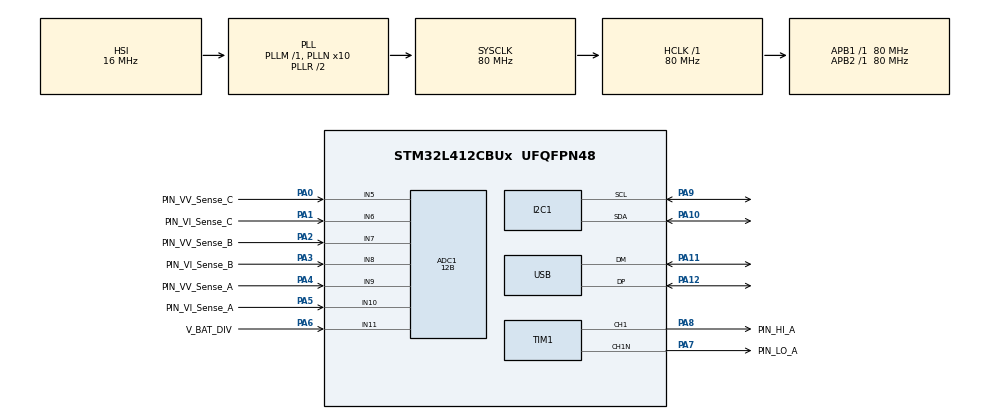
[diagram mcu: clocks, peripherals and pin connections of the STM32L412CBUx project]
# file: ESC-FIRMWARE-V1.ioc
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ADC1.Channel-0\#ChannelRegularConversion=ADC_CHANNEL_11
ADC1.ClockPrescaler=ADC_CLOCK_ASYNC_DIV1
ADC1.ContinuousConvMode=ENABLE
ADC1.DMAContinuousRequests=ENABLE
ADC1.NbrOfConversionFlag=1
ADC1.OffsetNumber-0\#ChannelRegularConversion=ADC_OFFSET_NONE
ADC1.Overrun=ADC_OVR_DATA_OVERWRITTEN
ADC1.Rank-0\#ChannelRegularConversion=1
ADC1.Resolution=ADC_RESOLUTION_12B
ADC1.SamplingTime-0\#ChannelRegularConversion=ADC_SAMPLETIME_2CYCLES_5
ADC1.master=1
Dma.ADC1.0.Direction=DMA_PERIPH_TO_MEMORY
Dma.ADC1.0.Instance=DMA1_Channel1
Dma.ADC1.0.MemDataAlignment=DMA_MDATAALIGN_HALFWORD
Dma.ADC1.0.MemInc=DMA_MINC_ENABLE
Dma.ADC1.0.Mode=DMA_CIRCULAR
Dma.ADC1.0.PeriphDataAlignment=DMA_PDATAALIGN_HALFWORD
Dma.ADC1.0.PeriphInc=DMA_PINC_DISABLE
Dma.ADC1.0.Priority=DMA_PRIORITY_LOW
Dma.Request0=ADC1
I2C1.Timing=0x10D19CE4
Mcu.Family=STM32L4
Mcu.Name=STM32L412CBUx
Mcu.Package=UFQFPN48
NVIC.DMA1_Channel1_IRQn=true\:0\:0\:false\:false\:true\:false\:true\:true
NVIC.PriorityGroup=NVIC_PRIORITYGROUP_4
NVIC.USB_IRQn=true\:0\:0\:false\:false\:true\:false\:true\:true
PA0.GPIO_Label=PIN_VV_Sense_C
PA0.Signal=ADCx_IN5
PA1.GPIO_Label=PIN_VI_Sense_C
PA1.Signal=ADCx_IN6
PA10.Mode=I2C
PA10.Signal=I2C1_SDA
PA11.Mode=Device
PA11.Signal=USB_DM
PA12.Mode=Device
PA12.Signal=USB_DP
PA13\ (JTMS/SWDIO).Mode=Serial_Wire
PA13\ (JTMS/SWDIO).Signal=SYS_JTMS-SWDIO
PA14\ (JTCK/SWCLK).Mode=Serial_Wire
PA14\ (JTCK/SWCLK).Signal=SYS_JTCK-SWCLK
PA2.GPIO_Label=PIN_VV_Sense_B
PA2.Signal=ADCx_IN7
PA3.GPIO_Label=PIN_VI_Sense_B
PA3.Signal=ADCx_IN8
PA4.GPIO_Label=PIN_VV_Sense_A
PA4.Signal=ADCx_IN9
PA5.GPIO_Label=PIN_VI_Sense_A
PA5.Signal=ADCx_IN10
PA6.GPIO_Label=V_BAT_DIV
PA6.Signal=ADCx_IN11
PA7.GPIO_Label=PIN_LO_A
PA7.Mode=PWM Generation1 CH1 CH1N
PA7.Signal=TIM1_CH1N
PA8.GPIO_Label=PIN_HI_A
PA8.Signal=S_TIM1_CH1
PA9.Mode=I2C
PA9.Signal=I2C1_SCL
PH0-OSC_IN\ (PH0).Mode=HSE-External-Oscillator
PH0-OSC_IN\ (PH0).Signal=RCC_OSC_IN
PH1-OSC_OUT\ (PH1).Mode=HSE-External-Oscillator
PH1-OSC_OUT\ (PH1).Signal=RCC_OSC_OUT
ProjectManager.HeapSize=0x200
ProjectManager.StackSize=0x400
ProjectManager.TargetToolchain=CMake
RCC.ADCFreq_Value=80000000
RCC.AHBFreq_Value=80000000
RCC.APB1Freq_Value=80000000
RCC.APB1TimFreq_Value=80000000
RCC.APB2Freq_Value=80000000
RCC.APB2TimFreq_Value=80000000
RCC.CortexFreq_Value=80000000
RCC.HCLKFreq_Value=80000000
RCC.HSE_VALUE=12000000
RCC.HSI48_VALUE=48000000
RCC.HSI_VALUE=16000000
RCC.LSE_VALUE=32768
RCC.MSIClockRange=RCC_MSIRANGE_11
RCC.MSI_VALUE=48000000
RCC.PLLN=10
RCC.PLLSourceVirtual=RCC_PLLSOURCE_HSI
RCC.SYSCLKFreq_VALUE=80000000
RCC.SYSCLKSource=RCC_SYSCLKSOURCE_PLLCLK
RCC.USBFreq_Value=48000000
RCC.VCOOutputFreq_Value=160000000
SH.ADCx_IN10.0=ADC1_IN10,IN10-Single-Ended
SH.ADCx_IN11.0=ADC1_IN11,IN11-Single-Ended
SH.ADCx_IN11.1=ADC2_IN11
SH.ADCx_IN5.0=ADC1_IN5,IN5-Single-Ended
SH.ADCx_IN6.0=ADC1_IN6,IN6-Single-Ended
SH.ADCx_IN7.0=ADC1_IN7,IN7-Single-Ended
SH.ADCx_IN8.0=ADC1_IN8,IN8-Single-Ended
SH.ADCx_IN9.0=ADC1_IN9,IN9-Single-Ended
SH.S_TIM1_CH1.0=TIM1_CH1,PWM Generation1 CH1 CH1N
TIM1.Channel-PWM\ Generation1\ CH1\ CH1N=TIM_CHANNEL_1
USB_DEVICE.CLASS_NAME_FS=CDC
USB_DEVICE.CONFIGURATION_STRING_CDC_FS=ESC FIRMWARE V1
USB_DEVICE.PRODUCT_STRING_CDC_FS=ESC COM PORT
USB_DEVICE.USBD_DEBUG_LEVEL=3
USB_DEVICE.VirtualMode=Cdc
USB_DEVICE.VirtualModeFS=Cdc_FS
VP_ADC1_Vbat_Input.Mode=IN-Vbat
VP_TIM1_VS_ClockSourceINT.Mode=Internal
VP_USB_DEVICE_VS_USB_DEVICE_CDC_FS.Mode=CDC_FS
board=custom

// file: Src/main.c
/* USER CODE BEGIN Header */
/**
 ******************************************************************************
 * @file           : main.c
 * @brief          : Main program body
 ******************************************************************************
 * @attention
 *
 * Copyright (c) 2024 STMicroelectronics.
 * All rights reserved.
 *
 * This software is licensed under terms that can be found in the LICENSE file
 * in the root directory of this software component.
 * If no LICENSE file comes with this software, it is provided AS-IS.
 *
 ******************************************************************************
 */
/* USER CODE END Header */
#include "main.h"
#include "usb_device.h"

/* USER CODE BEGIN PD */
#define ADC_BUF_LEN 4096
/* USER CODE END PD */

ADC_HandleTypeDef hadc1;
DMA_HandleTypeDef hdma_adc1;

I2C_HandleTypeDef hi2c1;

TIM_HandleTypeDef htim1;

/* USER CODE BEGIN PV */
uint16_t adc_buf[ADC_BUF_LEN];
/* USER CODE END PV */

void SystemClock_Config(void);
static void MX_GPIO_Init(void);
static void MX_DMA_Init(void);
static void MX_ADC1_Init(void);
static void MX_I2C1_Init(void);
static void MX_TIM1_Init(void);

int main(void)
{

  /* MCU Configuration--------------------------------------------------------*/

  /* Reset of all peripherals, Initializes the Flash interface and the Systick. */
  HAL_Init();

  /* Configure the system clock */
  SystemClock_Config();

  /* Initialize all configured peripherals */
  MX_GPIO_Init();
  MX_DMA_Init();
  MX_USB_DEVICE_Init();
  MX_ADC1_Init();
  MX_I2C1_Init();
  MX_TIM1_Init();
  /* USER CODE BEGIN 2 */
  HAL_Delay(200);
  printf("ESC_FIRMWARE_V1\n");
  /* USER CODE END 2 */

  /* Infinite loop */
  while (1)
  {

  }
}

// Called when first half of buffer is filled
void HAL_ADC_ConvHalfCpltCallback(ADC_HandleTypeDef *hadc)
{
  printf("first half of buffer is filled\n");
}

// Called when buffer is completely filled
void HAL_ADC_ConvCpltCallback(ADC_HandleTypeDef *hadc)
{
  printf("buffer is completely filled\n");
}

void SystemClock_Config(void)
{
  RCC_OscInitTypeDef RCC_OscInitStruct = {0};
  RCC_ClkInitTypeDef RCC_ClkInitStruct = {0};

  /** Configure the main internal regulator output voltage
   */
  if (HAL_PWREx_ControlVoltageScaling(PWR_REGULATOR_VOLTAGE_SCALE1) != HAL_OK)
  {
    Error_Handler();
  }

  /** Initializes the RCC Oscillators according to the specified parameters
   * in the RCC_OscInitTypeDef structure.
   */
  RCC_OscInitStruct.OscillatorType = RCC_OSCILLATORTYPE_HSI | RCC_OSCILLATORTYPE_MSI;
  RCC_OscInitStruct.HSIState = RCC_HSI_ON;
  RCC_OscInitStruct.HSICalibrationValue = RCC_HSICALIBRATION_DEFAULT;
  RCC_OscInitStruct.MSIState = RCC_MSI_ON;
  RCC_OscInitStruct.MSICalibrationValue = 0;
  RCC_OscInitStruct.MSIClockRange = RCC_MSIRANGE_11;
  RCC_OscInitStruct.PLL.PLLState = RCC_PLL_ON;
  RCC_OscInitStruct.PLL.PLLSource = RCC_PLLSOURCE_HSI;
  RCC_OscInitStruct.PLL.PLLM = 1;
  RCC_OscInitStruct.PLL.PLLN = 10;
  RCC_OscInitStruct.PLL.PLLQ = RCC_PLLQ_DIV2;
  RCC_OscInitStruct.PLL.PLLR = RCC_PLLR_DIV2;
  if (HAL_RCC_OscConfig(&RCC_OscInitStruct) != HAL_OK)
  {
    Error_Handler();
  }

  /** Initializes the CPU, AHB and APB buses clocks
   */
  RCC_ClkInitStruct.ClockType = RCC_CLOCKTYPE_HCLK | RCC_CLOCKTYPE_SYSCLK | RCC_CLOCKTYPE_PCLK1 | RCC_CLOCKTYPE_PCLK2;
  RCC_ClkInitStruct.SYSCLKSource = RCC_SYSCLKSOURCE_PLLCLK;
  RCC_ClkInitStruct.AHBCLKDivider = RCC_SYSCLK_DIV1;
  RCC_ClkInitStruct.APB1CLKDivider = RCC_HCLK_DIV1;
  RCC_ClkInitStruct.APB2CLKDivider = RCC_HCLK_DIV1;

  if (HAL_RCC_ClockConfig(&RCC_ClkInitStruct, FLASH_LATENCY_4) != HAL_OK)
  {
    Error_Handler();
  }
}

static void MX_ADC1_Init(void)
{

  ADC_MultiModeTypeDef multimode = {0};
  ADC_ChannelConfTypeDef sConfig = {0};

  /** Common config
   */
  hadc1.Instance = ADC1;
  hadc1.Init.ClockPrescaler = ADC_CLOCK_ASYNC_DIV1;
  hadc1.Init.Resolution = ADC_RESOLUTION_12B;
  hadc1.Init.DataAlign = ADC_DATAALIGN_RIGHT;
  hadc1.Init.ScanConvMode = ADC_SCAN_DISABLE;
  hadc1.Init.EOCSelection = ADC_EOC_SINGLE_CONV;
  hadc1.Init.LowPowerAutoWait = DISABLE;
  hadc1.Init.ContinuousConvMode = ENABLE;
  hadc1.Init.NbrOfConversion = 1;
  hadc1.Init.DiscontinuousConvMode = DISABLE;
  hadc1.Init.ExternalTrigConv = ADC_SOFTWARE_START;
  hadc1.Init.ExternalTrigConvEdge = ADC_EXTERNALTRIGCONVEDGE_NONE;
  hadc1.Init.DMAContinuousRequests = ENABLE;
  hadc1.Init.Overrun = ADC_OVR_DATA_OVERWRITTEN;
  hadc1.Init.OversamplingMode = DISABLE;
  if (HAL_ADC_Init(&hadc1) != HAL_OK)
  {
    Error_Handler();
  }

  /** Configure the ADC multi-mode
   */
  multimode.Mode = ADC_MODE_INDEPENDENT;
  if (HAL_ADCEx_MultiModeConfigChannel(&hadc1, &multimode) != HAL_OK)
  {
    Error_Handler();
  }

  /** Configure Regular Channel
   */
  sConfig.Channel = ADC_CHANNEL_11;
  sConfig.Rank = ADC_REGULAR_RANK_1;
  sConfig.SamplingTime = ADC_SAMPLETIME_2CYCLES_5;
  sConfig.SingleDiff = ADC_SINGLE_ENDED;
  sConfig.OffsetNumber = ADC_OFFSET_NONE;
  sConfig.Offset = 0;
  if (HAL_ADC_ConfigChannel(&hadc1, &sConfig) != HAL_OK)
  {
    Error_Handler();
  }
}

static void MX_I2C1_Init(void)
{

  hi2c1.Instance = I2C1;
  hi2c1.Init.Timing = 0x10D19CE4;
  hi2c1.Init.OwnAddress1 = 0;
  hi2c1.Init.AddressingMode = I2C_ADDRESSINGMODE_7BIT;
  hi2c1.Init.DualAddressMode = I2C_DUALADDRESS_DISABLE;
  hi2c1.Init.OwnAddress2 = 0;
  hi2c1.Init.OwnAddress2Masks = I2C_OA2_NOMASK;
  hi2c1.Init.GeneralCallMode = I2C_GENERALCALL_DISABLE;
  hi2c1.Init.NoStretchMode = I2C_NOSTRETCH_DISABLE;
  if (HAL_I2C_Init(&hi2c1) != HAL_OK)
  {
    Error_Handler();
  }

  /** Configure Analogue filter
   */
  if (HAL_I2CEx_ConfigAnalogFilter(&hi2c1, I2C_ANALOGFILTER_ENABLE) != HAL_OK)
  {
    Error_Handler();
  }

  /** Configure Digital filter
   */
  if (HAL_I2CEx_ConfigDigitalFilter(&hi2c1, 0) != HAL_OK)
  {
    Error_Handler();
  }
}

static void MX_TIM1_Init(void)
{

  TIM_ClockConfigTypeDef sClockSourceConfig = {0};
  TIM_MasterConfigTypeDef sMasterConfig = {0};
  TIM_OC_InitTypeDef sConfigOC = {0};
  TIM_BreakDeadTimeConfigTypeDef sBreakDeadTimeConfig = {0};

  htim1.Instance = TIM1;
  htim1.Init.Prescaler = 0;
  htim1.Init.CounterMode = TIM_COUNTERMODE_UP;
  htim1.Init.Period = 65535;
  htim1.Init.ClockDivision = TIM_CLOCKDIVISION_DIV1;
  htim1.Init.RepetitionCounter = 0;
  htim1.Init.AutoReloadPreload = TIM_AUTORELOAD_PRELOAD_DISABLE;
  if (HAL_TIM_Base_Init(&htim1) != HAL_OK)
  {
    Error_Handler();
  }
  sClockSourceConfig.ClockSource = TIM_CLOCKSOURCE_INTERNAL;
  if (HAL_TIM_ConfigClockSource(&htim1, &sClockSourceConfig) != HAL_OK)
  {
    Error_Handler();
  }
  if (HAL_TIM_PWM_Init(&htim1) != HAL_OK)
  {
    Error_Handler();
  }
  sMasterConfig.MasterOutputTrigger = TIM_TRGO_RESET;
  sMasterConfig.MasterOutputTrigger2 = TIM_TRGO2_RESET;
  sMasterConfig.MasterSlaveMode = TIM_MASTERSLAVEMODE_DISABLE;
  if (HAL_TIMEx_MasterConfigSynchronization(&htim1, &sMasterConfig) != HAL_OK)
  {
    Error_Handler();
  }
  sConfigOC.OCMode = TIM_OCMODE_PWM1;
  sConfigOC.Pulse = 0;
  sConfigOC.OCPolarity = TIM_OCPOLARITY_HIGH;
  sConfigOC.OCNPolarity = TIM_OCNPOLARITY_HIGH;
  sConfigOC.OCFastMode = TIM_OCFAST_DISABLE;
  sConfigOC.OCIdleState = TIM_OCIDLESTATE_RESET;
  sConfigOC.OCNIdleState = TIM_OCNIDLESTATE_RESET;
  if (HAL_TIM_PWM_ConfigChannel(&htim1, &sConfigOC, TIM_CHANNEL_1) != HAL_OK)
  {
    Error_Handler();
  }
  sBreakDeadTimeConfig.OffStateRunMode = TIM_OSSR_DISABLE;
  sBreakDeadTimeConfig.OffStateIDLEMode = TIM_OSSI_DISABLE;
  sBreakDeadTimeConfig.LockLevel = TIM_LOCKLEVEL_OFF;
  sBreakDeadTimeConfig.DeadTime = 0;
  sBreakDeadTimeConfig.BreakState = TIM_BREAK_DISABLE;
  sBreakDeadTimeConfig.BreakPolarity = TIM_BREAKPOLARITY_HIGH;
  sBreakDeadTimeConfig.BreakFilter = 0;
  sBreakDeadTimeConfig.Break2State = TIM_BREAK2_DISABLE;
  sBreakDeadTimeConfig.Break2Polarity = TIM_BREAK2POLARITY_HIGH;
  sBreakDeadTimeConfig.Break2Filter = 0;
  sBreakDeadTimeConfig.AutomaticOutput = TIM_AUTOMATICOUTPUT_DISABLE;
  if (HAL_TIMEx_ConfigBreakDeadTime(&htim1, &sBreakDeadTimeConfig) != HAL_OK)
  {
    Error_Handler();
  }
  HAL_TIM_MspPostInit(&htim1);
}

static void MX_DMA_Init(void)
{

  /* DMA controller clock enable */
  __HAL_RCC_DMA1_CLK_ENABLE();

  /* DMA interrupt init */
  /* DMA1_Channel1_IRQn interrupt configuration */
  HAL_NVIC_SetPriority(DMA1_Channel1_IRQn, 0, 0);
  HAL_NVIC_EnableIRQ(DMA1_Channel1_IRQn);
}

static void MX_GPIO_Init(void)
{
  GPIO_InitTypeDef GPIO_InitStruct = {0};

  /* GPIO Ports Clock Enable */
  __HAL_RCC_GPIOH_CLK_ENABLE();
  __HAL_RCC_GPIOA_CLK_ENABLE();

  /*Configure GPIO pin : V_BAT_DIV_Pin */
  GPIO_InitStruct.Pin = V_BAT_DIV_Pin;
  GPIO_InitStruct.Mode = GPIO_MODE_ANALOG_ADC_CONTROL;
  GPIO_InitStruct.Pull = GPIO_NOPULL;
  HAL_GPIO_Init(V_BAT_DIV_GPIO_Port, &GPIO_InitStruct);

}

void Error_Handler(void)
{
  __disable_irq();
  while (1)
  {
  }
}
